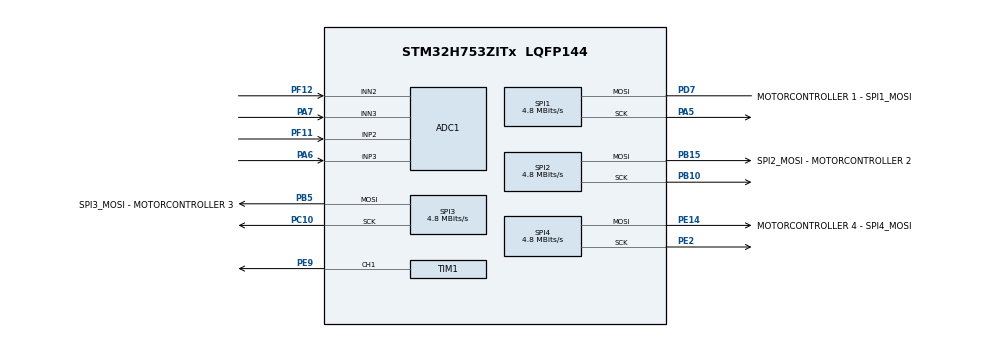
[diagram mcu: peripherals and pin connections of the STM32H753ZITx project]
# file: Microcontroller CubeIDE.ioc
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ADC1.Channel-0\#ChannelRegularConversion=ADC_CHANNEL_2
ADC1.Channel-1\#ChannelRegularConversion=ADC_CHANNEL_3
ADC1.ContinuousConvMode=ENABLE
ADC1.ConversionDataManagement=ADC_CONVERSIONDATA_DMA_CIRCULAR
ADC1.NbrOfConversion=2
ADC1.NbrOfConversionFlag=1
ADC1.OffsetNumber-0\#ChannelRegularConversion=ADC_OFFSET_NONE
ADC1.OffsetNumber-1\#ChannelRegularConversion=ADC_OFFSET_NONE
ADC1.OffsetSignedSaturation-0\#ChannelRegularConversion=DISABLE
ADC1.OffsetSignedSaturation-1\#ChannelRegularConversion=DISABLE
ADC1.Rank-0\#ChannelRegularConversion=1
ADC1.Rank-1\#ChannelRegularConversion=2
ADC1.SamplingTime-0\#ChannelRegularConversion=ADC_SAMPLETIME_387CYCLES_5
ADC1.SamplingTime-1\#ChannelRegularConversion=ADC_SAMPLETIME_387CYCLES_5
ADC1.SingleDiff-0\#ChannelRegularConversion=ADC_DIFFERENTIAL_ENDED
ADC1.SingleDiff-1\#ChannelRegularConversion=ADC_DIFFERENTIAL_ENDED
ADC1.master=1
CORTEX_M7.CPU_DCache=Disabled
CORTEX_M7.CPU_ICache=Disabled
CORTEX_M7.MPU_Control=MPU_PRIVILEGED_DEFAULT
CORTEX_M7.default_mode_Activation=1
Dma.ADC1.2.Direction=DMA_PERIPH_TO_MEMORY
Dma.ADC1.2.EventEnable=DISABLE
Dma.ADC1.2.FIFOMode=DMA_FIFOMODE_DISABLE
Dma.ADC1.2.Instance=DMA1_Stream2
Dma.ADC1.2.MemDataAlignment=DMA_MDATAALIGN_HALFWORD
Dma.ADC1.2.MemInc=DMA_MINC_ENABLE
Dma.ADC1.2.Mode=DMA_CIRCULAR
Dma.ADC1.2.PeriphDataAlignment=DMA_PDATAALIGN_HALFWORD
Dma.ADC1.2.PeriphInc=DMA_PINC_DISABLE
Dma.ADC1.2.Polarity=HAL_DMAMUX_REQ_GEN_RISING
Dma.ADC1.2.Priority=DMA_PRIORITY_MEDIUM
Dma.ADC1.2.RequestNumber=1
Dma.ADC1.2.SignalID=NONE
Dma.ADC1.2.SyncEnable=DISABLE
Dma.ADC1.2.SyncPolarity=HAL_DMAMUX_SYNC_NO_EVENT
Dma.ADC1.2.SyncRequestNumber=1
Dma.ADC1.2.SyncSignalID=NONE
Dma.Request0=SPI1_TX
Dma.Request1=SPI1_RX
Dma.Request2=ADC1
Dma.SPI1_RX.1.Direction=DMA_PERIPH_TO_MEMORY
Dma.SPI1_RX.1.EventEnable=DISABLE
Dma.SPI1_RX.1.FIFOMode=DMA_FIFOMODE_DISABLE
Dma.SPI1_RX.1.Instance=DMA1_Stream1
Dma.SPI1_RX.1.MemDataAlignment=DMA_MDATAALIGN_BYTE
Dma.SPI1_RX.1.MemInc=DMA_MINC_ENABLE
Dma.SPI1_RX.1.Mode=DMA_NORMAL
Dma.SPI1_RX.1.PeriphDataAlignment=DMA_PDATAALIGN_BYTE
Dma.SPI1_RX.1.PeriphInc=DMA_PINC_DISABLE
Dma.SPI1_RX.1.Polarity=HAL_DMAMUX_REQ_GEN_RISING
Dma.SPI1_RX.1.Priority=DMA_PRIORITY_VERY_HIGH
Dma.SPI1_RX.1.RequestNumber=1
Dma.SPI1_RX.1.SignalID=NONE
Dma.SPI1_RX.1.SyncEnable=DISABLE
Dma.SPI1_RX.1.SyncPolarity=HAL_DMAMUX_SYNC_NO_EVENT
Dma.SPI1_RX.1.SyncRequestNumber=1
Dma.SPI1_RX.1.SyncSignalID=NONE
Dma.SPI1_TX.0.Direction=DMA_MEMORY_TO_PERIPH
Dma.SPI1_TX.0.EventEnable=DISABLE
Dma.SPI1_TX.0.FIFOMode=DMA_FIFOMODE_DISABLE
Dma.SPI1_TX.0.Instance=DMA1_Stream0
Dma.SPI1_TX.0.MemDataAlignment=DMA_MDATAALIGN_BYTE
Dma.SPI1_TX.0.MemInc=DMA_MINC_ENABLE
Dma.SPI1_TX.0.Mode=DMA_NORMAL
Dma.SPI1_TX.0.PeriphDataAlignment=DMA_PDATAALIGN_BYTE
Dma.SPI1_TX.0.PeriphInc=DMA_PINC_DISABLE
Dma.SPI1_TX.0.Polarity=HAL_DMAMUX_REQ_GEN_RISING
Dma.SPI1_TX.0.Priority=DMA_PRIORITY_VERY_HIGH
Dma.SPI1_TX.0.RequestNumber=1
Dma.SPI1_TX.0.SignalID=NONE
Dma.SPI1_TX.0.SyncEnable=DISABLE
Dma.SPI1_TX.0.SyncPolarity=HAL_DMAMUX_SYNC_NO_EVENT
Dma.SPI1_TX.0.SyncRequestNumber=1
Dma.SPI1_TX.0.SyncSignalID=NONE
FREERTOS.Tasks01=defaultTask,24,512,RTOS_Main,Default,NULL,Dynamic,NULL,NULL;Blinky,8,512,RTOS_Blinky,Default,NULL,Dynamic,NULL,NULL;CAN,8,128,RTOS_CAN,Default,NULL,Dynamic,NULL,NULL
FREERTOS.configCHECK_FOR_STACK_OVERFLOW=2
FREERTOS.configUSE_NEWLIB_REENTRANT=1
Mcu.Family=STM32H7
Mcu.Name=STM32H753ZITx
Mcu.Package=LQFP144
NUCLEO-H753ZI.BUTTON=1
NUCLEO-H753ZI.LD1=true
NUCLEO-H753ZI.LD2=true
NUCLEO-H753ZI.LD3=true
NUCLEO-H753ZI.VCP=true
NVIC.DMA1_Stream0_IRQn=true\:5\:0\:false\:false\:true\:true\:false\:true\:true
NVIC.DMA1_Stream1_IRQn=true\:5\:0\:false\:false\:true\:true\:false\:true\:true
NVIC.DMA1_Stream2_IRQn=true\:5\:0\:false\:false\:true\:true\:false\:true\:true
NVIC.EXTI15_10_IRQn=true\:5\:0\:false\:false\:true\:true\:false\:true\:true
NVIC.PriorityGroup=NVIC_PRIORITYGROUP_4
NVIC.SPI1_IRQn=true\:5\:0\:false\:false\:true\:true\:false\:true\:true
NVIC.TIM7_IRQn=true\:15\:0\:false\:false\:true\:false\:false\:true\:true
NVIC.TimeBase=TIM7_IRQn
NVIC.TimeBaseIP=TIM7
PA5.Mode=Simplex_Bidirectional_Master
PA5.Signal=SPI1_SCK
PA6.Signal=ADCx_INP3
PA7.Signal=ADCx_INN3
PB10.Mode=TX_Only_Simplex_Unidirect_Master
PB10.Signal=SPI2_SCK
PB15.GPIO_Label=SPI2_MOSI - MOTORCONTROLLER 2
PB15.Mode=TX_Only_Simplex_Unidirect_Master
PB15.Signal=SPI2_MOSI
PB5.GPIO_Label=SPI3_MOSI - MOTORCONTROLLER 3
PB5.Mode=TX_Only_Simplex_Unidirect_Master
PB5.Signal=SPI3_MOSI
PC10.Mode=TX_Only_Simplex_Unidirect_Master
PC10.Signal=SPI3_SCK
PC14-OSC32_IN\ (OSC32_IN).Signal=RCC_OSC32_IN
PC15-OSC32_OUT\ (OSC32_OUT).Signal=RCC_OSC32_OUT
PD7.GPIO_Label=MOTORCONTROLLER 1 - SPI1_MOSI
PD7.GPIO_PuPd=GPIO_NOPULL
PD7.GPIO_Speed=GPIO_SPEED_FREQ_VERY_HIGH
PD7.Mode=Simplex_Bidirectional_Master
PD7.Signal=SPI1_MOSI
PE14.GPIO_Label=MOTORCONTROLLER 4 - SPI4_MOSI
PE14.Mode=TX_Only_Simplex_Unidirect_Master
PE14.Signal=SPI4_MOSI
PE2.Mode=TX_Only_Simplex_Unidirect_Master
PE2.Signal=SPI4_SCK
PE9.Signal=S_TIM1_CH1
PF11.Mode=IN2-Differential
PF11.Signal=ADC1_INP2
PF12.Mode=IN2-Differential
PF12.Signal=ADC1_INN2
PH0-OSC_IN\ (PH0).Signal=RCC_OSC_IN
PH1-OSC_OUT\ (PH1).Signal=RCC_OSC_OUT
ProjectManager.HeapSize=0x200
ProjectManager.StackSize=0x400
ProjectManager.TargetToolchain=STM32CubeIDE
RCC.ADCFreq_Value=19200000
RCC.APB1Freq_Value=64000000
RCC.APB2Freq_Value=64000000
RCC.APB3Freq_Value=64000000
RCC.APB4Freq_Value=64000000
RCC.CortexFreq_Value=64000000
RCC.DIVM1=4
RCC.DIVM2=4
RCC.DIVM3=4
RCC.DIVN1=12
RCC.DIVN2=12
RCC.DIVN3=12
RCC.DIVP2=10
RCC.DIVQ1=10
RCC.DIVQ2=10
RCC.DIVQ3=10
RCC.HCLKFreq_Value=64000000
RCC.HSE_VALUE=8000000
RCC.PLL2FRACN=0
RCC.PLL3FRACN=0
RCC.PLLFRACN=0
RCC.PWR_Regulator_Voltage_Scale=PWR_REGULATOR_VOLTAGE_SCALE2
RCC.SYSCLKFreq_VALUE=64000000
RCC.Spi45ClockSelection=RCC_SPI45CLKSOURCE_PLL2
RCC.USBFreq_Value=19200000
SH.ADCx_INN3.0=ADC1_INN3,IN3-Differential
SH.ADCx_INP3.0=ADC1_INP3,IN3-Differential
SH.S_TIM1_CH1.0=TIM1_CH1,PWM Generation1 CH1
SPI1.BaudRatePrescaler=SPI_BAUDRATEPRESCALER_4
SPI1.CLKPhase=SPI_PHASE_1EDGE
SPI1.CLKPolarity=SPI_POLARITY_LOW
SPI1.CRCCalculation=SPI_CRCCALCULATION_DISABLE
SPI1.CalculateBaudRate=4.8 MBits/s
SPI1.DataSize=SPI_DATASIZE_8BIT
SPI1.Direction=SPI_DIRECTION_1LINE
SPI1.FirstBit=SPI_FIRSTBIT_MSB
SPI1.MasterKeepIOState=SPI_MASTER_KEEP_IO_STATE_ENABLE
SPI1.Mode=SPI_MODE_MASTER
SPI1.NSSPMode=SPI_NSS_PULSE_DISABLE
SPI1.VirtualType=VM_MASTER
SPI2.BaudRatePrescaler=SPI_BAUDRATEPRESCALER_4
SPI2.CalculateBaudRate=4.8 MBits/s
SPI2.Direction=SPI_DIRECTION_2LINES_TXONLY
SPI2.Mode=SPI_MODE_MASTER
SPI2.VirtualType=VM_MASTER
SPI3.BaudRatePrescaler=SPI_BAUDRATEPRESCALER_4
SPI3.CalculateBaudRate=4.8 MBits/s
SPI3.Direction=SPI_DIRECTION_2LINES_TXONLY
SPI3.Mode=SPI_MODE_MASTER
SPI3.VirtualType=VM_MASTER
SPI4.BaudRatePrescaler=SPI_BAUDRATEPRESCALER_4
SPI4.CalculateBaudRate=4.8 MBits/s
SPI4.Direction=SPI_DIRECTION_2LINES_TXONLY
SPI4.Mode=SPI_MODE_MASTER
SPI4.VirtualType=VM_MASTER
TIM1.AutoReloadPreload=TIM_AUTORELOAD_PRELOAD_ENABLE
TIM1.Channel-PWM\ Generation1\ CH1=TIM_CHANNEL_1
TIM1.Period=19999
TIM1.Prescaler=63
TIM1.Pulse-PWM\ Generation1\ CH1=1000
VP_FREERTOS_VS_CMSIS_V2.Mode=CMSIS_V2
VP_MEMORYMAP_VS_MEMORYMAP.Mode=CurAppReg
VP_NUCLEO-H753ZI_VS_BSP_COMMON.Mode=COMMON
VP_SYS_VS_tim7.Mode=TIM7
board=NUCLEO-H753ZI

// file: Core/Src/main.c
/* USER CODE BEGIN Header */
/**
  ******************************************************************************
  * @file           : main.c
  * @brief          : Main program body
  ******************************************************************************
  * @attention
  *
  * Copyright (c) 2026 STMicroelectronics.
  * All rights reserved.
  *
  * This software is licensed under terms that can be found in the LICENSE file
  * in the root directory of this software component.
  * If no LICENSE file comes with this software, it is provided AS-IS.
  *
  ******************************************************************************
  */
/* USER CODE END Header */
#include "main.h"
#include "FreeRTOS.h"
#include "cmsis_os2.h"

/* USER CODE BEGIN Includes */
#include "Controller.h"
/* USER CODE END Includes */

COM_InitTypeDef BspCOMInit;
ADC_HandleTypeDef hadc1;
DMA_HandleTypeDef hdma_adc1;

SPI_HandleTypeDef hspi1;
SPI_HandleTypeDef hspi2;
SPI_HandleTypeDef hspi3;
SPI_HandleTypeDef hspi4;
DMA_HandleTypeDef hdma_spi1_tx;
DMA_HandleTypeDef hdma_spi1_rx;

TIM_HandleTypeDef htim1;

/* Definitions for defaultTask */
osThreadId_t defaultTaskHandle;
const osThreadAttr_t defaultTask_attributes = {
  .name = "defaultTask",
  .stack_size = 512 * 4,
  .priority = (osPriority_t) osPriorityNormal,
};
/* Definitions for Blinky */
osThreadId_t BlinkyHandle;
const osThreadAttr_t Blinky_attributes = {
  .name = "Blinky",
  .stack_size = 512 * 4,
  .priority = (osPriority_t) osPriorityLow,
};
/* Definitions for CAN */
osThreadId_t CANHandle;
const osThreadAttr_t CAN_attributes = {
  .name = "CAN",
  .stack_size = 128 * 4,
  .priority = (osPriority_t) osPriorityLow,
};

void SystemClock_Config(void);
void PeriphCommonClock_Config(void);
static void MPU_Config(void);
static void MX_GPIO_Init(void);
static void MX_DMA_Init(void);
static void MX_TIM1_Init(void);
static void MX_SPI1_Init(void);
static void MX_SPI2_Init(void);
static void MX_SPI3_Init(void);
static void MX_SPI4_Init(void);
static void MX_ADC1_Init(void);
void RTOS_Main(void *argument);
void RTOS_Blinky(void *argument);
void RTOS_CAN(void *argument);

int main(void)
{

  /* MPU Configuration--------------------------------------------------------*/
  MPU_Config();

  /* MCU Configuration--------------------------------------------------------*/

  /* Reset of all peripherals, Initializes the Flash interface and the Systick. */
  HAL_Init();

  /* Configure the system clock */
  SystemClock_Config();

  /* Configure the peripherals common clocks */
  PeriphCommonClock_Config();

  /* Initialize all configured peripherals */
  MX_GPIO_Init();
  MX_DMA_Init();
  MX_TIM1_Init();
  MX_SPI1_Init();
  MX_SPI2_Init();
  MX_SPI3_Init();
  MX_SPI4_Init();
  MX_ADC1_Init();

  /* Init scheduler */
  osKernelInitialize();

  /* Create the thread(s) */
  /* creation of defaultTask */
  defaultTaskHandle = osThreadNew(RTOS_Main, NULL, &defaultTask_attributes);

  /* creation of Blinky */
  BlinkyHandle = osThreadNew(RTOS_Blinky, NULL, &Blinky_attributes);

  /* creation of CAN */
  CANHandle = osThreadNew(RTOS_CAN, NULL, &CAN_attributes);

  /* Initialize leds */
  BSP_LED_Init(LED_GREEN);
  BSP_LED_Init(LED_YELLOW);
  BSP_LED_Init(LED_RED);

  /* Initialize USER push-button, will be used to trigger an interrupt each time it's pressed.*/
  BSP_PB_Init(BUTTON_USER, BUTTON_MODE_EXTI);

  /* Initialize COM1 port (115200, 8 bits (7-bit data + 1 stop bit), no parity */
  BspCOMInit.BaudRate   = 115200;
  BspCOMInit.WordLength = COM_WORDLENGTH_8B;
  BspCOMInit.StopBits   = COM_STOPBITS_1;
  BspCOMInit.Parity     = COM_PARITY_NONE;
  BspCOMInit.HwFlowCtl  = COM_HWCONTROL_NONE;
  if (BSP_COM_Init(COM1, &BspCOMInit) != BSP_ERROR_NONE)
  {
    Error_Handler();
  }

  /* Start scheduler */
  osKernelStart();

  /* We should never get here as control is now taken by the scheduler */

  /* Infinite loop */
  while (1)
  {

  }
}

void SystemClock_Config(void)
{
  RCC_OscInitTypeDef RCC_OscInitStruct = {0};
  RCC_ClkInitTypeDef RCC_ClkInitStruct = {0};

  /** Supply configuration update enable
  */
  HAL_PWREx_ConfigSupply(PWR_LDO_SUPPLY);

  /** Configure the main internal regulator output voltage
  */
  __HAL_PWR_VOLTAGESCALING_CONFIG(PWR_REGULATOR_VOLTAGE_SCALE2);

  while(!__HAL_PWR_GET_FLAG(PWR_FLAG_VOSRDY)) {}

  /** Initializes the RCC Oscillators according to the specified parameters
  * in the RCC_OscInitTypeDef structure.
  */
  RCC_OscInitStruct.OscillatorType = RCC_OSCILLATORTYPE_HSI;
  RCC_OscInitStruct.HSIState = RCC_HSI_DIV1;
  RCC_OscInitStruct.HSICalibrationValue = RCC_HSICALIBRATION_DEFAULT;
  RCC_OscInitStruct.PLL.PLLState = RCC_PLL_ON;
  RCC_OscInitStruct.PLL.PLLSource = RCC_PLLSOURCE_HSI;
  RCC_OscInitStruct.PLL.PLLM = 4;
  RCC_OscInitStruct.PLL.PLLN = 12;
  RCC_OscInitStruct.PLL.PLLP = 2;
  RCC_OscInitStruct.PLL.PLLQ = 10;
  RCC_OscInitStruct.PLL.PLLR = 2;
  RCC_OscInitStruct.PLL.PLLRGE = RCC_PLL1VCIRANGE_3;
  RCC_OscInitStruct.PLL.PLLVCOSEL = RCC_PLL1VCOWIDE;
  RCC_OscInitStruct.PLL.PLLFRACN = 0;
  if (HAL_RCC_OscConfig(&RCC_OscInitStruct) != HAL_OK)
  {
    Error_Handler();
  }

  /** Initializes the CPU, AHB and APB buses clocks
  */
  RCC_ClkInitStruct.ClockType = RCC_CLOCKTYPE_HCLK|RCC_CLOCKTYPE_SYSCLK
                              |RCC_CLOCKTYPE_PCLK1|RCC_CLOCKTYPE_PCLK2
                              |RCC_CLOCKTYPE_D3PCLK1|RCC_CLOCKTYPE_D1PCLK1;
  RCC_ClkInitStruct.SYSCLKSource = RCC_SYSCLKSOURCE_HSI;
  RCC_ClkInitStruct.SYSCLKDivider = RCC_SYSCLK_DIV1;
  RCC_ClkInitStruct.AHBCLKDivider = RCC_HCLK_DIV1;
  RCC_ClkInitStruct.APB3CLKDivider = RCC_APB3_DIV1;
  RCC_ClkInitStruct.APB1CLKDivider = RCC_APB1_DIV1;
  RCC_ClkInitStruct.APB2CLKDivider = RCC_APB2_DIV1;
  RCC_ClkInitStruct.APB4CLKDivider = RCC_APB4_DIV1;

  if (HAL_RCC_ClockConfig(&RCC_ClkInitStruct, FLASH_LATENCY_1) != HAL_OK)
  {
    Error_Handler();
  }
}

void PeriphCommonClock_Config(void)
{
  RCC_PeriphCLKInitTypeDef PeriphClkInitStruct = {0};

  /** Initializes the peripherals clock
  */
  PeriphClkInitStruct.PeriphClockSelection = RCC_PERIPHCLK_ADC|RCC_PERIPHCLK_SPI4;
  PeriphClkInitStruct.PLL2.PLL2M = 4;
  PeriphClkInitStruct.PLL2.PLL2N = 12;
  PeriphClkInitStruct.PLL2.PLL2P = 10;
  PeriphClkInitStruct.PLL2.PLL2Q = 10;
  PeriphClkInitStruct.PLL2.PLL2R = 2;
  PeriphClkInitStruct.PLL2.PLL2RGE = RCC_PLL2VCIRANGE_3;
  PeriphClkInitStruct.PLL2.PLL2VCOSEL = RCC_PLL2VCOWIDE;
  PeriphClkInitStruct.PLL2.PLL2FRACN = 0;
  PeriphClkInitStruct.Spi45ClockSelection = RCC_SPI45CLKSOURCE_PLL2;
  PeriphClkInitStruct.AdcClockSelection = RCC_ADCCLKSOURCE_PLL2;
  if (HAL_RCCEx_PeriphCLKConfig(&PeriphClkInitStruct) != HAL_OK)
  {
    Error_Handler();
  }
}

static void MX_ADC1_Init(void)
{

  ADC_MultiModeTypeDef multimode = {0};
  ADC_ChannelConfTypeDef sConfig = {0};

  /** Common config
  */
  hadc1.Instance = ADC1;
  hadc1.Init.ClockPrescaler = ADC_CLOCK_ASYNC_DIV1;
  hadc1.Init.Resolution = ADC_RESOLUTION_16B;
  hadc1.Init.ScanConvMode = ADC_SCAN_ENABLE;
  hadc1.Init.EOCSelection = ADC_EOC_SINGLE_CONV;
  hadc1.Init.LowPowerAutoWait = DISABLE;
  hadc1.Init.ContinuousConvMode = ENABLE;
  hadc1.Init.NbrOfConversion = 2;
  hadc1.Init.DiscontinuousConvMode = DISABLE;
  hadc1.Init.ExternalTrigConv = ADC_SOFTWARE_START;
  hadc1.Init.ExternalTrigConvEdge = ADC_EXTERNALTRIGCONVEDGE_NONE;
  hadc1.Init.ConversionDataManagement = ADC_CONVERSIONDATA_DMA_CIRCULAR;
  hadc1.Init.Overrun = ADC_OVR_DATA_PRESERVED;
  hadc1.Init.LeftBitShift = ADC_LEFTBITSHIFT_NONE;
  hadc1.Init.OversamplingMode = DISABLE;
  hadc1.Init.Oversampling.Ratio = 1;
  if (HAL_ADC_Init(&hadc1) != HAL_OK)
  {
    Error_Handler();
  }

  /** Configure the ADC multi-mode
  */
  multimode.Mode = ADC_MODE_INDEPENDENT;
  if (HAL_ADCEx_MultiModeConfigChannel(&hadc1, &multimode) != HAL_OK)
  {
    Error_Handler();
  }

  /** Configure Regular Channel
  */
  sConfig.Channel = ADC_CHANNEL_2;
  sConfig.Rank = ADC_REGULAR_RANK_1;
  sConfig.SamplingTime = ADC_SAMPLETIME_387CYCLES_5;
  sConfig.SingleDiff = ADC_DIFFERENTIAL_ENDED;
  sConfig.OffsetNumber = ADC_OFFSET_NONE;
  sConfig.Offset = 0;
  sConfig.OffsetSignedSaturation = DISABLE;
  if (HAL_ADC_ConfigChannel(&hadc1, &sConfig) != HAL_OK)
  {
    Error_Handler();
  }

  /** Configure Regular Channel
  */
  sConfig.Channel = ADC_CHANNEL_3;
  sConfig.Rank = ADC_REGULAR_RANK_2;
  if (HAL_ADC_ConfigChannel(&hadc1, &sConfig) != HAL_OK)
  {
    Error_Handler();
  }

}

static void MX_SPI1_Init(void)
{

  /* SPI1 parameter configuration*/
  hspi1.Instance = SPI1;
  hspi1.Init.Mode = SPI_MODE_MASTER;
  hspi1.Init.Direction = SPI_DIRECTION_1LINE;
  hspi1.Init.DataSize = SPI_DATASIZE_8BIT;
  hspi1.Init.CLKPolarity = SPI_POLARITY_LOW;
  hspi1.Init.CLKPhase = SPI_PHASE_1EDGE;
  hspi1.Init.NSS = SPI_NSS_SOFT;
  hspi1.Init.BaudRatePrescaler = SPI_BAUDRATEPRESCALER_4;
  hspi1.Init.FirstBit = SPI_FIRSTBIT_MSB;
  hspi1.Init.TIMode = SPI_TIMODE_DISABLE;
  hspi1.Init.CRCCalculation = SPI_CRCCALCULATION_DISABLE;
  hspi1.Init.CRCPolynomial = 0x0;
  hspi1.Init.NSSPMode = SPI_NSS_PULSE_DISABLE;
  hspi1.Init.NSSPolarity = SPI_NSS_POLARITY_LOW;
  hspi1.Init.FifoThreshold = SPI_FIFO_THRESHOLD_01DATA;
  hspi1.Init.TxCRCInitializationPattern = SPI_CRC_INITIALIZATION_ALL_ZERO_PATTERN;
  hspi1.Init.RxCRCInitializationPattern = SPI_CRC_INITIALIZATION_ALL_ZERO_PATTERN;
  hspi1.Init.MasterSSIdleness = SPI_MASTER_SS_IDLENESS_00CYCLE;
  hspi1.Init.MasterInterDataIdleness = SPI_MASTER_INTERDATA_IDLENESS_00CYCLE;
  hspi1.Init.MasterReceiverAutoSusp = SPI_MASTER_RX_AUTOSUSP_DISABLE;
  hspi1.Init.MasterKeepIOState = SPI_MASTER_KEEP_IO_STATE_ENABLE;
  hspi1.Init.IOSwap = SPI_IO_SWAP_DISABLE;
  if (HAL_SPI_Init(&hspi1) != HAL_OK)
  {
    Error_Handler();
  }

}

static void MX_SPI2_Init(void)
{

  /* SPI2 parameter configuration*/
  hspi2.Instance = SPI2;
  hspi2.Init.Mode = SPI_MODE_MASTER;
  hspi2.Init.Direction = SPI_DIRECTION_2LINES_TXONLY;
  hspi2.Init.DataSize = SPI_DATASIZE_4BIT;
  hspi2.Init.CLKPolarity = SPI_POLARITY_LOW;
  hspi2.Init.CLKPhase = SPI_PHASE_1EDGE;
  hspi2.Init.NSS = SPI_NSS_SOFT;
  hspi2.Init.BaudRatePrescaler = SPI_BAUDRATEPRESCALER_4;
  hspi2.Init.FirstBit = SPI_FIRSTBIT_MSB;
  hspi2.Init.TIMode = SPI_TIMODE_DISABLE;
  hspi2.Init.CRCCalculation = SPI_CRCCALCULATION_DISABLE;
  hspi2.Init.CRCPolynomial = 0x0;
  hspi2.Init.NSSPMode = SPI_NSS_PULSE_ENABLE;
  hspi2.Init.NSSPolarity = SPI_NSS_POLARITY_LOW;
  hspi2.Init.FifoThreshold = SPI_FIFO_THRESHOLD_01DATA;
  hspi2.Init.TxCRCInitializationPattern = SPI_CRC_INITIALIZATION_ALL_ZERO_PATTERN;
  hspi2.Init.RxCRCInitializationPattern = SPI_CRC_INITIALIZATION_ALL_ZERO_PATTERN;
  hspi2.Init.MasterSSIdleness = SPI_MASTER_SS_IDLENESS_00CYCLE;
  hspi2.Init.MasterInterDataIdleness = SPI_MASTER_INTERDATA_IDLENESS_00CYCLE;
  hspi2.Init.MasterReceiverAutoSusp = SPI_MASTER_RX_AUTOSUSP_DISABLE;
  hspi2.Init.MasterKeepIOState = SPI_MASTER_KEEP_IO_STATE_DISABLE;
  hspi2.Init.IOSwap = SPI_IO_SWAP_DISABLE;
  if (HAL_SPI_Init(&hspi2) != HAL_OK)
  {
    Error_Handler();
  }

}

static void MX_SPI3_Init(void)
{

  /* SPI3 parameter configuration*/
  hspi3.Instance = SPI3;
  hspi3.Init.Mode = SPI_MODE_MASTER;
  hspi3.Init.Direction = SPI_DIRECTION_2LINES_TXONLY;
  hspi3.Init.DataSize = SPI_DATASIZE_4BIT;
  hspi3.Init.CLKPolarity = SPI_POLARITY_LOW;
  hspi3.Init.CLKPhase = SPI_PHASE_1EDGE;
  hspi3.Init.NSS = SPI_NSS_SOFT;
  hspi3.Init.BaudRatePrescaler = SPI_BAUDRATEPRESCALER_4;
  hspi3.Init.FirstBit = SPI_FIRSTBIT_MSB;
  hspi3.Init.TIMode = SPI_TIMODE_DISABLE;
  hspi3.Init.CRCCalculation = SPI_CRCCALCULATION_DISABLE;
  hspi3.Init.CRCPolynomial = 0x0;
  hspi3.Init.NSSPMode = SPI_NSS_PULSE_ENABLE;
  hspi3.Init.NSSPolarity = SPI_NSS_POLARITY_LOW;
  hspi3.Init.FifoThreshold = SPI_FIFO_THRESHOLD_01DATA;
  hspi3.Init.TxCRCInitializationPattern = SPI_CRC_INITIALIZATION_ALL_ZERO_PATTERN;
  hspi3.Init.RxCRCInitializationPattern = SPI_CRC_INITIALIZATION_ALL_ZERO_PATTERN;
  hspi3.Init.MasterSSIdleness = SPI_MASTER_SS_IDLENESS_00CYCLE;
  hspi3.Init.MasterInterDataIdleness = SPI_MASTER_INTERDATA_IDLENESS_00CYCLE;
  hspi3.Init.MasterReceiverAutoSusp = SPI_MASTER_RX_AUTOSUSP_DISABLE;
  hspi3.Init.MasterKeepIOState = SPI_MASTER_KEEP_IO_STATE_DISABLE;
  hspi3.Init.IOSwap = SPI_IO_SWAP_DISABLE;
  if (HAL_SPI_Init(&hspi3) != HAL_OK)
  {
    Error_Handler();
  }

}

static void MX_SPI4_Init(void)
{

  /* SPI4 parameter configuration*/
  hspi4.Instance = SPI4;
  hspi4.Init.Mode = SPI_MODE_MASTER;
  hspi4.Init.Direction = SPI_DIRECTION_2LINES_TXONLY;
  hspi4.Init.DataSize = SPI_DATASIZE_4BIT;
  hspi4.Init.CLKPolarity = SPI_POLARITY_LOW;
  hspi4.Init.CLKPhase = SPI_PHASE_1EDGE;
  hspi4.Init.NSS = SPI_NSS_SOFT;
  hspi4.Init.BaudRatePrescaler = SPI_BAUDRATEPRESCALER_4;
  hspi4.Init.FirstBit = SPI_FIRSTBIT_MSB;
  hspi4.Init.TIMode = SPI_TIMODE_DISABLE;
  hspi4.Init.CRCCalculation = SPI_CRCCALCULATION_DISABLE;
  hspi4.Init.CRCPolynomial = 0x0;
  hspi4.Init.NSSPMode = SPI_NSS_PULSE_ENABLE;
  hspi4.Init.NSSPolarity = SPI_NSS_POLARITY_LOW;
  hspi4.Init.FifoThreshold = SPI_FIFO_THRESHOLD_01DATA;
  hspi4.Init.TxCRCInitializationPattern = SPI_CRC_INITIALIZATION_ALL_ZERO_PATTERN;
  hspi4.Init.RxCRCInitializationPattern = SPI_CRC_INITIALIZATION_ALL_ZERO_PATTERN;
  hspi4.Init.MasterSSIdleness = SPI_MASTER_SS_IDLENESS_00CYCLE;
  hspi4.Init.MasterInterDataIdleness = SPI_MASTER_INTERDATA_IDLENESS_00CYCLE;
  hspi4.Init.MasterReceiverAutoSusp = SPI_MASTER_RX_AUTOSUSP_DISABLE;
  hspi4.Init.MasterKeepIOState = SPI_MASTER_KEEP_IO_STATE_DISABLE;
  hspi4.Init.IOSwap = SPI_IO_SWAP_DISABLE;
  if (HAL_SPI_Init(&hspi4) != HAL_OK)
  {
    Error_Handler();
  }

}

static void MX_TIM1_Init(void)
{

  TIM_MasterConfigTypeDef sMasterConfig = {0};
  TIM_OC_InitTypeDef sConfigOC = {0};
  TIM_BreakDeadTimeConfigTypeDef sBreakDeadTimeConfig = {0};

  htim1.Instance = TIM1;
  htim1.Init.Prescaler = 63;
  htim1.Init.CounterMode = TIM_COUNTERMODE_UP;
  htim1.Init.Period = 19999;
  htim1.Init.ClockDivision = TIM_CLOCKDIVISION_DIV1;
  htim1.Init.RepetitionCounter = 0;
  htim1.Init.AutoReloadPreload = TIM_AUTORELOAD_PRELOAD_ENABLE;
  if (HAL_TIM_PWM_Init(&htim1) != HAL_OK)
  {
    Error_Handler();
  }
  sMasterConfig.MasterOutputTrigger = TIM_TRGO_RESET;
  sMasterConfig.MasterOutputTrigger2 = TIM_TRGO2_RESET;
  sMasterConfig.MasterSlaveMode = TIM_MASTERSLAVEMODE_DISABLE;
  if (HAL_TIMEx_MasterConfigSynchronization(&htim1, &sMasterConfig) != HAL_OK)
  {
    Error_Handler();
  }
  sConfigOC.OCMode = TIM_OCMODE_PWM1;
  sConfigOC.Pulse = 1000;
  sConfigOC.OCPolarity = TIM_OCPOLARITY_HIGH;
  sConfigOC.OCNPolarity = TIM_OCNPOLARITY_HIGH;
  sConfigOC.OCFastMode = TIM_OCFAST_DISABLE;
  sConfigOC.OCIdleState = TIM_OCIDLESTATE_RESET;
  sConfigOC.OCNIdleState = TIM_OCNIDLESTATE_RESET;
  if (HAL_TIM_PWM_ConfigChannel(&htim1, &sConfigOC, TIM_CHANNEL_1) != HAL_OK)
  {
    Error_Handler();
  }
  sBreakDeadTimeConfig.OffStateRunMode = TIM_OSSR_DISABLE;
  sBreakDeadTimeConfig.OffStateIDLEMode = TIM_OSSI_DISABLE;
  sBreakDeadTimeConfig.LockLevel = TIM_LOCKLEVEL_OFF;
  sBreakDeadTimeConfig.DeadTime = 0;
  sBreakDeadTimeConfig.BreakState = TIM_BREAK_DISABLE;
  sBreakDeadTimeConfig.BreakPolarity = TIM_BREAKPOLARITY_HIGH;
  sBreakDeadTimeConfig.BreakFilter = 0;
  sBreakDeadTimeConfig.Break2State = TIM_BREAK2_DISABLE;
  sBreakDeadTimeConfig.Break2Polarity = TIM_BREAK2POLARITY_HIGH;
  sBreakDeadTimeConfig.Break2Filter = 0;
  sBreakDeadTimeConfig.AutomaticOutput = TIM_AUTOMATICOUTPUT_DISABLE;
  if (HAL_TIMEx_ConfigBreakDeadTime(&htim1, &sBreakDeadTimeConfig) != HAL_OK)
  {
    Error_Handler();
  }
  HAL_TIM_MspPostInit(&htim1);

}

static void MX_DMA_Init(void)
{

  /* DMA controller clock enable */
  __HAL_RCC_DMA1_CLK_ENABLE();

  /* DMA interrupt init */
  /* DMA1_Stream0_IRQn interrupt configuration */
  HAL_NVIC_SetPriority(DMA1_Stream0_IRQn, 5, 0);
  HAL_NVIC_EnableIRQ(DMA1_Stream0_IRQn);
  /* DMA1_Stream1_IRQn interrupt configuration */
  HAL_NVIC_SetPriority(DMA1_Stream1_IRQn, 5, 0);
  HAL_NVIC_EnableIRQ(DMA1_Stream1_IRQn);
  /* DMA1_Stream2_IRQn interrupt configuration */
  HAL_NVIC_SetPriority(DMA1_Stream2_IRQn, 5, 0);
  HAL_NVIC_EnableIRQ(DMA1_Stream2_IRQn);

}

static void MX_GPIO_Init(void)
{

  /* GPIO Ports Clock Enable */
  __HAL_RCC_GPIOE_CLK_ENABLE();
  __HAL_RCC_GPIOC_CLK_ENABLE();
  __HAL_RCC_GPIOH_CLK_ENABLE();
  __HAL_RCC_GPIOA_CLK_ENABLE();
  __HAL_RCC_GPIOF_CLK_ENABLE();
  __HAL_RCC_GPIOB_CLK_ENABLE();
  __HAL_RCC_GPIOD_CLK_ENABLE();

}

void RTOS_Main(void *argument)
{
  /* USER CODE BEGIN 5 */
	Controller_Init();
  /* Infinite loop */
  for(;;)
  {
	  Controller_Main();
    osDelay(50);
  }
  /* USER CODE END 5 */
}

void RTOS_Blinky(void *argument)
{
  /* USER CODE BEGIN RTOS_Blinky */
  /* Infinite loop */
  for(;;)
  {
	  Controller_Blinky();
//    osDelay(1000/1000);
	  osDelay(250);
  }
  /* USER CODE END RTOS_Blinky */
}

void RTOS_CAN(void *argument)
{
  /* USER CODE BEGIN RTOS_CAN */
  /* Infinite loop */
  for(;;)
  {
	  Controller_CAN();
    osDelay(2000);
  }
  /* USER CODE END RTOS_CAN */
}

 /* MPU Configuration */

void MPU_Config(void)
{
  MPU_Region_InitTypeDef MPU_InitStruct = {0};

  /* Disables the MPU */
  HAL_MPU_Disable();

  /** Initializes and configures the Region and the memory to be protected
  */
  MPU_InitStruct.Enable = MPU_REGION_ENABLE;
  MPU_InitStruct.Number = MPU_REGION_NUMBER0;
  MPU_InitStruct.BaseAddress = 0x0;
  MPU_InitStruct.Size = MPU_REGION_SIZE_4GB;
  MPU_InitStruct.SubRegionDisable = 0x87;
  MPU_InitStruct.TypeExtField = MPU_TEX_LEVEL0;
  MPU_InitStruct.AccessPermission = MPU_REGION_NO_ACCESS;
  MPU_InitStruct.DisableExec = MPU_INSTRUCTION_ACCESS_DISABLE;
  MPU_InitStruct.IsShareable = MPU_ACCESS_SHAREABLE;
  MPU_InitStruct.IsCacheable = MPU_ACCESS_NOT_CACHEABLE;
  MPU_InitStruct.IsBufferable = MPU_ACCESS_NOT_BUFFERABLE;

  HAL_MPU_ConfigRegion(&MPU_InitStruct);
  /* Enables the MPU */
  HAL_MPU_Enable(MPU_PRIVILEGED_DEFAULT);

}

void HAL_TIM_PeriodElapsedCallback(TIM_HandleTypeDef *htim)
{
  if (htim->Instance == TIM7)
  {
    HAL_IncTick();
  }
}

void Error_Handler(void)
{
  __disable_irq();
  while (1)
  {
  }
}
